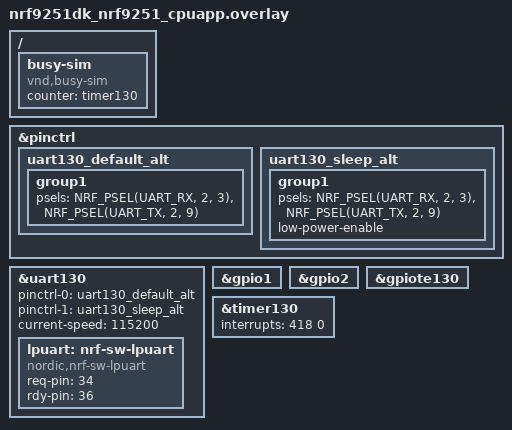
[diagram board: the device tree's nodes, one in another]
/*
 * Copyright (c) 2026 Nordic Semiconductor ASA
 *
 * SPDX-License-Identifier: LicenseRef-Nordic-5-Clause
 */

/* Two GPIO loopbacks are required:
 * UART RX-TX Pins: P2.03 - P2.09
 * Request-Response Pins: P1.02 - P1.04
 */

&pinctrl {
	uart130_default_alt: uart130_default_alt {
		group1 {
			psels = <NRF_PSEL(UART_RX, 2, 3)>,
				<NRF_PSEL(UART_TX, 2, 9)>;
		};
	};

	uart130_sleep_alt: uart130_sleep_alt {
		group1 {
			psels = <NRF_PSEL(UART_RX, 2, 3)>,
				<NRF_PSEL(UART_TX, 2, 9)>;
			low-power-enable;
		};
	};
};

&uart130 {
	status = "okay";
	pinctrl-0 = <&uart130_default_alt>;
	pinctrl-1 = <&uart130_sleep_alt>;
	pinctrl-names = "default", "sleep";
	current-speed = <115200>;

	lpuart: nrf-sw-lpuart {
		compatible = "nordic,nrf-sw-lpuart";
		status = "okay";
		req-pin = <34>;
		rdy-pin = <36>;
	};
};

&gpio1 {
	status = "okay";
};

&gpio2 {
	status = "okay";
};

&gpiote130 {
	status = "okay";
};

&timer130 {
	status = "okay";
	interrupts = <418 0>;
};

/ {
	busy-sim {
		compatible = "vnd,busy-sim";
		status = "okay";
		counter = <&timer130>;
	};
};
